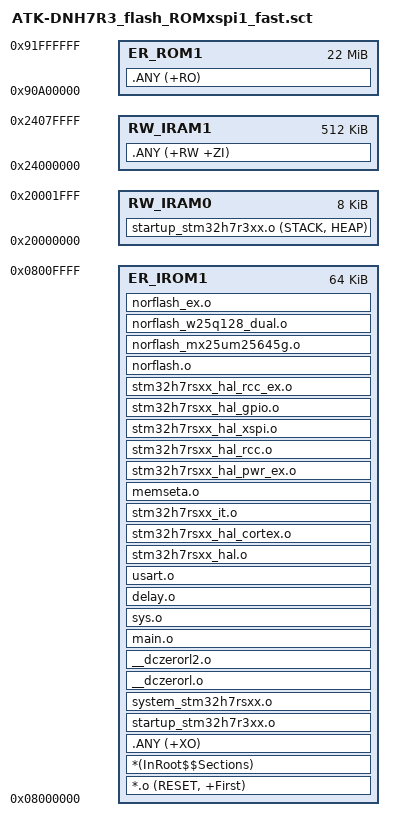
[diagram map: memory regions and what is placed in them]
/**
 ****************************************************************************************************
 * @file        ATK-DNH7R3_flash_ROMxspi1_fast.sct
 * @brief       Scatter-loading description for X-CUBE-AI without reprogramming external weights
 ****************************************************************************************************
 */

LR_IROM1 0x08000000 0x00010000 {
    ER_IROM1 0x08000000 0x00010000 {
        *.o (RESET, +First)
        *(InRoot$$Sections)
        .ANY (+XO)

        startup_stm32h7r3xx.o
        system_stm32h7rsxx.o
        __dczerorl.o
        __dczerorl2.o
        main.o
        sys.o
        delay.o
        usart.o
        stm32h7rsxx_hal.o
        stm32h7rsxx_hal_cortex.o
        stm32h7rsxx_it.o
        memseta.o
        stm32h7rsxx_hal_pwr_ex.o
        stm32h7rsxx_hal_rcc.o
        stm32h7rsxx_hal_xspi.o
        stm32h7rsxx_hal_gpio.o
        stm32h7rsxx_hal_rcc_ex.o

        norflash.o
        norflash_mx25um25645g.o
        norflash_w25q128_dual.o
        norflash_ex.o
    }
    RW_IRAM0 0x20000000 0x00002000 {
        startup_stm32h7r3xx.o (STACK, HEAP)
    }
    RW_IRAM1 0x24000000 0x00080000 {
        .ANY (+RW +ZI)
    }
}

LR_ROM1 0x90A00000 0x01600000 {
    ER_ROM1 0x90A00000 0x01600000 {
        .ANY (+RO)
    }
}
